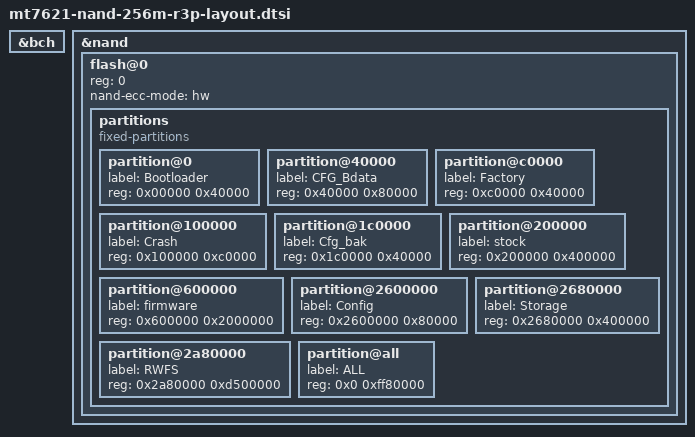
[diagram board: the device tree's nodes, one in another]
// SPDX-License-Identifier: GPL-2.0-only
/* Xiaomi R3P 256MB NAND layout, 256K bootloader, firmware 32MB @ 0x600000 */

&bch {
	status = "okay";
};

&nand {
	status = "okay";

	flash@0 {
		reg = <0>;
		nand-ecc-mode = "hw";
		partitions {
			compatible = "fixed-partitions";
			#address-cells = <1>;
			#size-cells = <1>;

			partition@0 {
				label = "Bootloader";
				reg = <0x00000 0x40000>; /* 256K */
			};

			partition@40000 {
				label = "CFG_Bdata";
				reg = <0x40000 0x80000>; /* 512K */
			};

			partition@c0000 {
				label = "Factory";
				reg = <0xc0000 0x40000>; /* 256K */
			};

			partition@100000 {
				label = "Crash";
				reg = <0x100000 0xc0000>; /* 768K */
			};

			partition@1c0000 {
				label = "Cfg_bak";
				reg = <0x1c0000 0x40000>; /* 256K */
			};

			partition@200000 {
				label = "stock";
				reg = <0x200000 0x400000>; /* 4MB */
			};

			partition@600000 {
				label = "firmware";
				reg = <0x600000 0x2000000>; /* 32MB */
			};

			partition@2600000 {
				label = "Config";
				reg = <0x2600000 0x80000>; /* 512K */
			};

			partition@2680000 {
				label = "Storage";
				reg = <0x2680000 0x400000>; /* 4MB */
			};

			partition@2a80000 {
				label = "RWFS";
				reg = <0x2a80000 0xd500000>; /* ~213MB */
			};

			partition@all {
				label = "ALL";
				reg = <0x0 0xff80000>; /* 255.5MB */
			};
		};
	};
};
